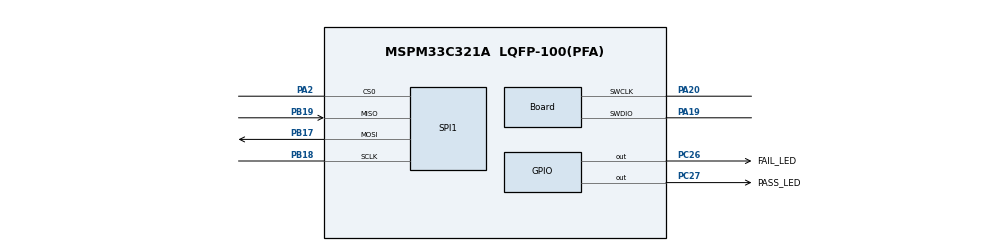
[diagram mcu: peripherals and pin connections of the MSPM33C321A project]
//@cliArgs --device "MSPM33C321A" --package "LQFP-100(PFA)" --part "Default"
//@v2CliArgs --device "MSPM33C321A" --package "LQFP-100(PFA)"
// @cliArgs --board /ti/boards/LP_MSPM33C321A --rtos nortos


/**
 * Import the modules used in this configuration.
 */
const GPIO   = scripting.addModule("/ti/driverlib/GPIO", {}, false);
const GPIO1  = GPIO.addInstance();
const SPI    = scripting.addModule("/ti/driverlib/SPI", {}, false);
const SPI1   = SPI.addInstance();
const SYSCTL = scripting.addModule("/ti/driverlib/SYSCTL");


/**
 * Write custom configuration values to the imported modules.
 */
GPIO1.$name                                 = "GPIO_LEDS";
GPIO1.associatedPins.create(2);
GPIO1.associatedPins[0].$name               = "FAIL_LED";
GPIO1.associatedPins[0].assignedPort        = "PORTC";
GPIO1.associatedPins[0].assignedPortSegment = "Upper";
GPIO1.associatedPins[0].assignedPin         = "26";
GPIO1.associatedPins[0].launchPadShortcut   = "LED2RedEn";
GPIO1.associatedPins[0].pin.$assign         = "PC26";
GPIO1.associatedPins[1].$name               = "PASS_LED";
GPIO1.associatedPins[1].launchPadShortcut   = "LED2GreenEn";
GPIO1.associatedPins[1].pin.$assign         = "PC27";

const Board                       = scripting.addModule("/ti/driverlib/Board", {}, false);
Board.peripheral.$assign          = "DEBUGSS";
Board.peripheral.swclkPin.$assign = "PA20";
Board.peripheral.swdioPin.$assign = "PA19";

SPI1.$name                              = "SPI_0";
SPI1.targetBitRate                      = 100000;
SPI1.mode                               = "PERIPHERAL";
SPI1.rxFifoThreshold                    = "DL_SPI_RX_FIFO_LEVEL_ONE_FRAME";
SPI1.txFifoThreshold                    = "DL_SPI_TX_FIFO_LEVEL_EMPTY";
SPI1.enabledInterrupts                  = ["RX"];
SPI1.peripheral.$assign                 = "UC2";
SPI1.peripheral.sclkPin.$assign         = "PB18";
SPI1.peripheral.mosiPin.$assign         = "PB17";
SPI1.peripheral.misoPin.$assign         = "PB19";
SPI1.peripheral.cs0Pin.$assign          = "PA2";
SPI1.sclkPinConfig.$name                = "ti_driverlib_gpio_GPIOPinGeneric0";
SPI1.sclkPinConfig.enableConfig         = true;
SPI1.mosiPinConfig.$name                = "ti_driverlib_gpio_GPIOPinGeneric1";
SPI1.mosiPinConfig.enableConfig         = true;
SPI1.misoPinConfig.$name                = "ti_driverlib_gpio_GPIOPinGeneric2";
SPI1.misoPinConfig.enableConfig         = true;
SPI1.cs0PinConfig.$name                 = "ti_driverlib_gpio_GPIOPinGeneric3";
SPI1.cs0PinConfig.enableConfig          = true;
SPI1.cs0PinConfig.internalResistor      = "PULL_UP";

SYSCTL.forceDefaultClkConfig = true;
SYSCTL.peripheral.$assign    = "SYSCTL";

const ProjectConfig              = scripting.addModule("/ti/project_config/ProjectConfig", {}, false);
ProjectConfig.migrationCondition = true;

ProjectConfig.genLinker  = true;
ProjectConfig.genStartup = true;
ProjectConfig.genOpts    = true;
ProjectConfig.genLibs    = true;
